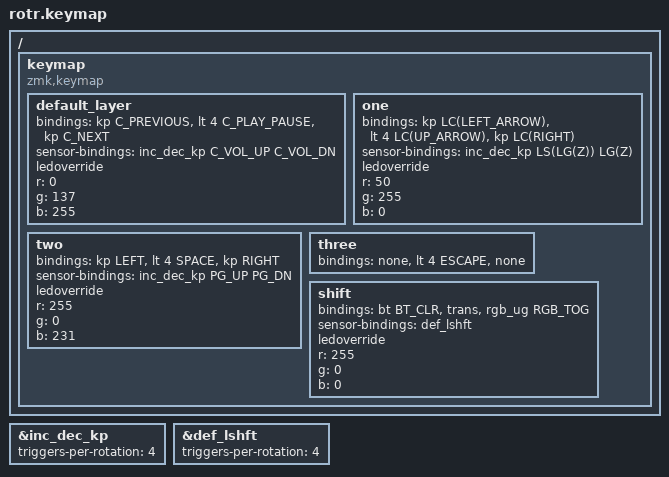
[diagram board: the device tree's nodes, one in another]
#include <behaviors.dtsi>
#include <dt-bindings/zmk/bt.h>
#include <dt-bindings/zmk/keys.h>
#include <dt-bindings/zmk/rgb.h>

&inc_dec_kp { triggers-per-rotation = <4>; };

&def_lshft { triggers-per-rotation = <4>; };

/ {
    keymap {
        compatible = "zmk,keymap";

        default_layer {
            //PREV | PLAY/PAUSE | NEXT

            bindings = <
&kp C_PREVIOUS  &lt 4 C_PLAY_PAUSE  &kp C_NEXT
            >;

            sensor-bindings = <&inc_dec_kp C_VOL_UP C_VOL_DN>;

            // BLUE

            ledoverride;
            r = <0>;
            g = <137>;
            b = <255>;
        };

        one {
            //PREV | PLAY/PAUSE | NEXT

            bindings = <
&kp LC(LEFT_ARROW)  &lt 4 LC(UP_ARROW)  &kp LC(RIGHT)
            >;

            sensor-bindings = <&inc_dec_kp LS(LG(Z)) LG(Z)>;

            // GREEN

            ledoverride;
            r = <50>;
            g = <255>;
            b = <0>;
        };

        two {
            //PREV | PLAY/PAUSE | NEXT

            bindings = <
&kp LEFT  &lt 4 SPACE  &kp RIGHT
            >;

            sensor-bindings = <&inc_dec_kp PG_UP PG_DN>;

            // PINK

            ledoverride;
            r = <255>;
            g = <0>;
            b = <231>;
        };

        three {
            //PREV | PLAY/PAUSE | NEXT

            bindings = <
&none  &lt 4 ESCAPE  &none
            >;
        };

        shift {
            //PREV | PLAY/PAUSE | NEXT

            bindings = <
&bt BT_CLR  &trans  &rgb_ug RGB_TOG
            >;

            sensor-bindings = <&def_lshft>;

            // RED

            ledoverride;
            r = <255>;
            g = <0>;
            b = <0>;
        };
    };
};
